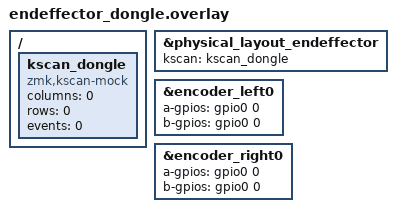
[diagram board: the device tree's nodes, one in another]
#include "endeffector.dtsi"

/ {
    kscan_dongle: kscan_dongle {
        compatible = "zmk,kscan-mock";
        columns = <0>;
        rows = <0>;
        events = <0>;
    };
};

&physical_layout_endeffector {
    kscan = <&kscan_dongle>;
};

// Assigning dummy pins to other part's encoders
// just to satisfy the devicetree requirements.
// No code will be compiled for these disabled encoders.
&encoder_left0 {
    a-gpios = <&gpio0 0 (GPIO_ACTIVE_HIGH | GPIO_PULL_UP)>;
    b-gpios = <&gpio0 0 (GPIO_ACTIVE_HIGH | GPIO_PULL_UP)>;
};
&encoder_right0 {
    a-gpios = <&gpio0 0 (GPIO_ACTIVE_HIGH | GPIO_PULL_UP)>;
    b-gpios = <&gpio0 0 (GPIO_ACTIVE_HIGH | GPIO_PULL_UP)>;
};

